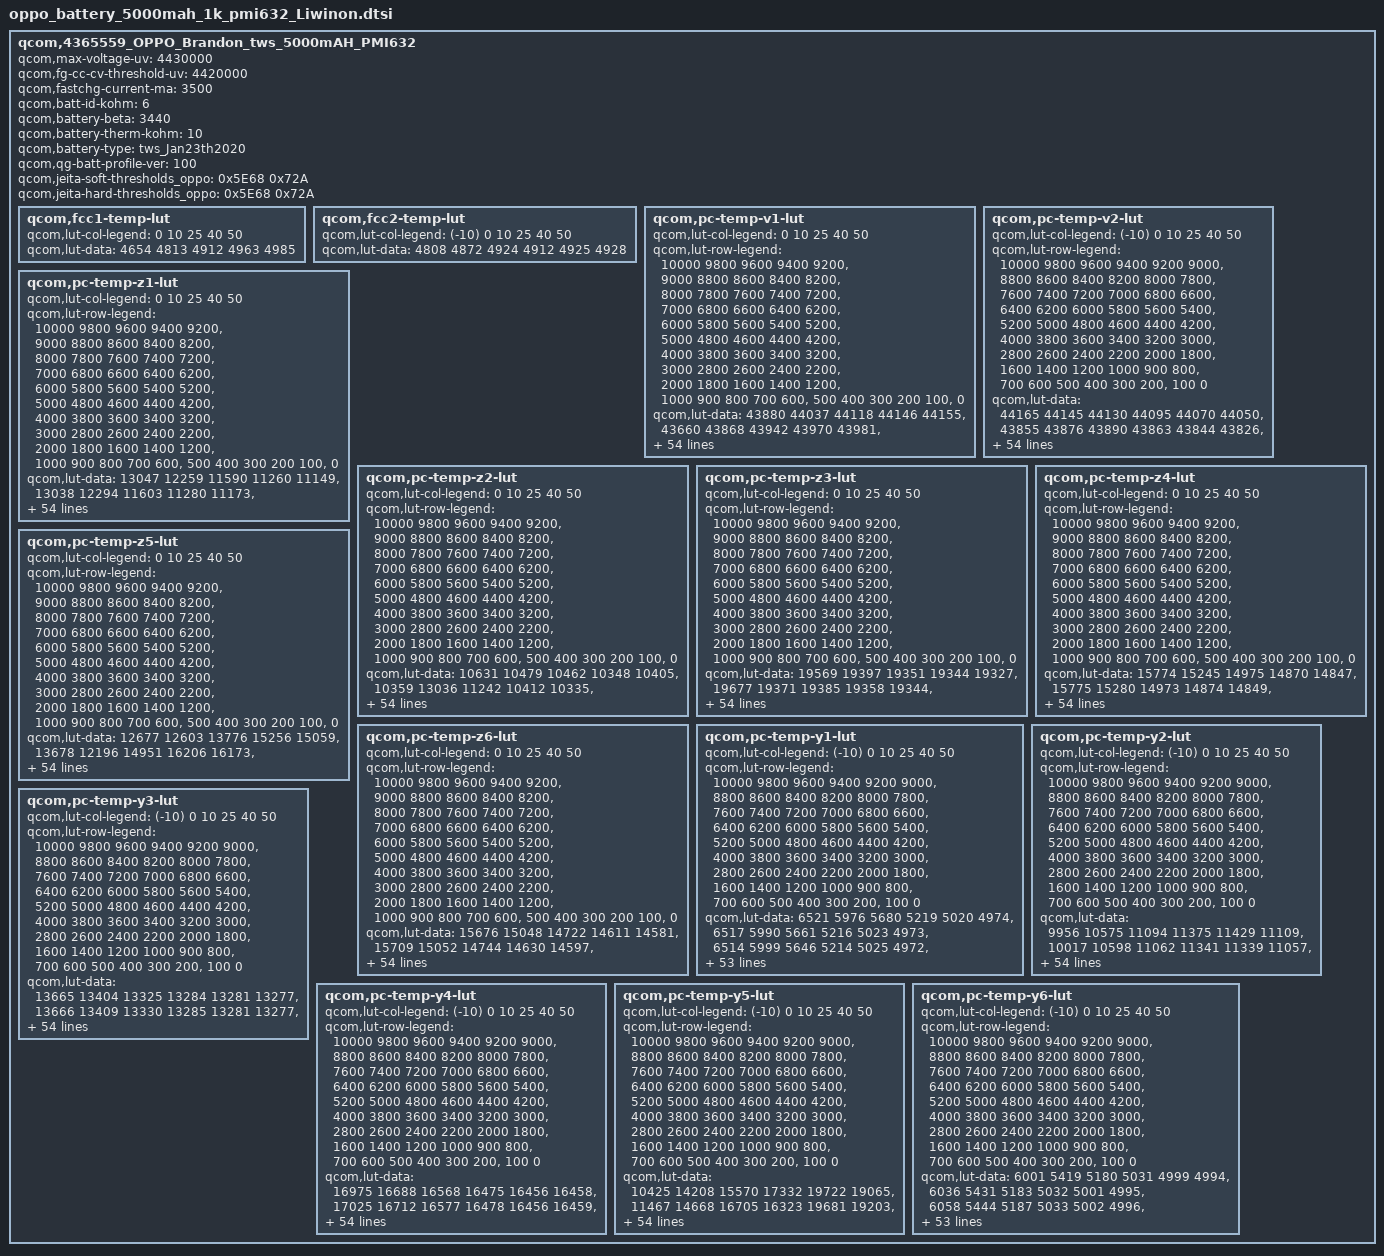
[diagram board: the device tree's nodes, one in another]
qcom,4365559_OPPO_Brandon_tws_5000mAH_PMI632 {
    /* 4365559_OPPO_Brandon_tws_5000mAH_PMI632_averaged_MasterSlave_Jan23th2020 */
    qcom,max-voltage-uv = <4430000>;
    qcom,fg-cc-cv-threshold-uv = <4420000>;
    qcom,fastchg-current-ma = <3500>;
    qcom,batt-id-kohm = <6>;
    qcom,battery-beta = <3440>;
    qcom,battery-therm-kohm = <10>;
    qcom,battery-type = "tws_Jan23th2020";
    qcom,qg-batt-profile-ver = <100>;
    qcom,jeita-soft-thresholds_oppo = <0x5E68 0x72A>;
    qcom,jeita-hard-thresholds_oppo = <0x5E68 0x72A>;

	qcom,fcc1-temp-lut {
		qcom,lut-col-legend = <0 10 25 40 50>;
		qcom,lut-data = <4654 4813 4912 4963 4985>;
	};

	qcom,fcc2-temp-lut {
		qcom,lut-col-legend = <(-10) 0 10 25 40 50>;
		qcom,lut-data = <4808 4872 4924 4912 4925 4928>;
	};

	qcom,pc-temp-v1-lut {
		qcom,lut-col-legend = <0 10 25 40 50>;
		qcom,lut-row-legend = <10000 9800 9600 9400 9200>,
			<9000 8800 8600 8400 8200>,
			<8000 7800 7600 7400 7200>,
			<7000 6800 6600 6400 6200>,
			<6000 5800 5600 5400 5200>,
			<5000 4800 4600 4400 4200>,
			<4000 3800 3600 3400 3200>,
			<3000 2800 2600 2400 2200>,
			<2000 1800 1600 1400 1200>,
			<1000 900 800 700 600>,
			<500 400 300 200 100>,
			<0>;
		qcom,lut-data = <43880 44037 44118 44146 44155>,
			<43660 43868 43942 43970 43981>,
			<43435 43650 43750 43783 43794>,
			<43204 43413 43544 43584 43595>,
			<42971 43181 43326 43372 43383>,
			<42737 42944 43095 43151 43161>,
			<42501 42705 42853 42916 42930>,
			<42265 42464 42611 42675 42691>,
			<42033 42222 42368 42434 42451>,
			<41803 41986 42125 42190 42207>,
			<41578 41754 41888 41950 41966>,
			<41359 41527 41655 41711 41728>,
			<41143 41305 41426 41477 41496>,
			<40934 41088 41197 41251 41267>,
			<40730 40876 40975 41031 41044>,
			<40533 40668 40768 40819 40828>,
			<40340 40469 40571 40614 40621>,
			<40154 40281 40378 40415 40420>,
			<39978 40101 40196 40229 40231>,
			<39814 39922 40009 40050 40053>,
			<39659 39747 39775 39843 39856>,
			<39507 39566 39473 39557 39593>,
			<39361 39351 39218 39281 39323>,
			<39217 39086 39059 39110 39142>,
			<39070 38872 38932 38984 39010>,
			<38923 38745 38819 38869 38890>,
			<38788 38648 38718 38757 38767>,
			<38663 38565 38625 38652 38651>,
			<38553 38493 38535 38552 38546>,
			<38470 38428 38449 38455 38449>,
			<38405 38369 38370 38367 38360>,
			<38351 38315 38297 38286 38279>,
			<38303 38265 38230 38211 38204>,
			<38262 38222 38171 38143 38133>,
			<38225 38181 38120 38079 38066>,
			<38193 38140 38069 38018 37998>,
			<38161 38101 38023 37961 37930>,
			<38118 38053 37972 37903 37858>,
			<38060 37983 37899 37825 37772>,
			<37986 37892 37801 37725 37668>,
			<37891 37790 37695 37615 37555>,
			<37765 37670 37579 37501 37438>,
			<37623 37531 37447 37373 37308>,
			<37466 37365 37284 37213 37150>,
			<37329 37231 37151 37085 37025>,
			<37211 37134 37066 37008 36955>,
			<37176 37105 37041 36980 36928>,
			<37144 37081 37022 36963 36908>,
			<37110 37056 36999 36939 36882>,
			<37068 36999 36937 36865 36797>,
			<36954 36767 36666 36577 36485>,
			<36639 36315 36214 36124 36036>,
			<36132 35730 35626 35544 35453>,
			<35451 34911 34820 34747 34656>,
			<34299 33565 33538 33497 33406>,
			<30000 30000 30000 30000 30000>;
	};

	qcom,pc-temp-v2-lut {
		qcom,lut-col-legend = <(-10) 0 10 25 40 50>;
		qcom,lut-row-legend = <10000 9800 9600 9400 9200 9000>,
			<8800 8600 8400 8200 8000 7800>,
			<7600 7400 7200 7000 6800 6600>,
			<6400 6200 6000 5800 5600 5400>,
			<5200 5000 4800 4600 4400 4200>,
			<4000 3800 3600 3400 3200 3000>,
			<2800 2600 2400 2200 2000 1800>,
			<1600 1400 1200 1000 900 800>,
			<700 600 500 400 300 200>,
			<100 0>;
		qcom,lut-data = <44165 44145 44130 44095 44070 44050>,
			<43855 43876 43890 43863 43844 43826>,
			<43564 43618 43653 43633 43618 43602>,
			<43295 43372 43421 43406 43394 43380>,
			<43051 43143 43195 43183 43173 43161>,
			<42811 42912 42965 42956 42948 42936>,
			<42559 42667 42723 42719 42712 42701>,
			<42302 42416 42475 42477 42470 42460>,
			<42055 42169 42229 42235 42229 42220>,
			<41821 41928 41984 41993 41988 41979>,
			<41590 41692 41744 41754 41749 41742>,
			<41353 41460 41508 41518 41514 41507>,
			<41112 41233 41279 41287 41283 41276>,
			<40869 41011 41059 41062 41059 41052>,
			<40629 40802 40851 40844 40841 40833>,
			<40388 40589 40643 40634 40630 40622>,
			<40140 40350 40423 40432 40428 40420>,
			<39884 40084 40195 40237 40233 40224>,
			<39635 39829 39957 40032 40037 40030>,
			<39401 39596 39696 39809 39839 39838>,
			<39177 39376 39445 39580 39634 39640>,
			<38973 39176 39234 39352 39402 39409>,
			<38788 38992 39049 39120 39146 39152>,
			<38621 38824 38884 38926 38940 38946>,
			<38470 38674 38737 38777 38791 38797>,
			<38329 38536 38604 38650 38666 38671>,
			<38219 38393 38479 38531 38548 38551>,
			<38143 38235 38363 38422 38440 38441>,
			<38081 38101 38258 38322 38342 38341>,
			<38022 38017 38163 38228 38250 38249>,
			<37966 37955 38077 38142 38166 38164>,
			<37910 37904 37992 38064 38090 38087>,
			<37856 37864 37907 37993 38021 38018>,
			<37800 37827 37834 37924 37949 37943>,
			<37743 37782 37783 37856 37866 37851>,
			<37683 37730 37739 37787 37775 37751>,
			<37620 37672 37691 37712 37680 37647>,
			<37553 37613 37642 37628 37577 37536>,
			<37480 37547 37583 37541 37479 37431>,
			<37405 37470 37508 37458 37394 37343>,
			<37325 37379 37415 37373 37313 37260>,
			<37242 37275 37306 37274 37214 37157>,
			<37161 37149 37170 37147 37086 37029>,
			<37081 37016 37021 37021 36966 36911>,
			<37001 36896 36864 36902 36863 36815>,
			<36922 36795 36777 36855 36827 36779>,
			<36877 36755 36744 36837 36814 36766>,
			<36830 36722 36711 36817 36796 36750>,
			<36775 36688 36658 36785 36763 36714>,
			<36711 36633 36556 36691 36647 36574>,
			<36614 36519 36303 36401 36314 36222>,
			<36449 36218 35833 35893 35809 35713>,
			<36165 35636 35160 35242 35156 35050>,
			<35715 34812 34181 34357 34251 34129>,
			<34797 33553 32647 32956 32934 32822>,
			<33915 31826 28647 27850 28081 28044>;
	};

	qcom,pc-temp-z1-lut {
		qcom,lut-col-legend = <0 10 25 40 50>;
		qcom,lut-row-legend = <10000 9800 9600 9400 9200>,
			<9000 8800 8600 8400 8200>,
			<8000 7800 7600 7400 7200>,
			<7000 6800 6600 6400 6200>,
			<6000 5800 5600 5400 5200>,
			<5000 4800 4600 4400 4200>,
			<4000 3800 3600 3400 3200>,
			<3000 2800 2600 2400 2200>,
			<2000 1800 1600 1400 1200>,
			<1000 900 800 700 600>,
			<500 400 300 200 100>,
			<0>;
		qcom,lut-data = <13047 12259 11590 11260 11149>,
			<13038 12294 11603 11280 11173>,
			<13028 12282 11606 11292 11189>,
			<13014 12267 11603 11294 11192>,
			<13000 12254 11599 11295 11193>,
			<12987 12239 11594 11294 11194>,
			<12973 12223 11588 11292 11194>,
			<12960 12205 11581 11289 11194>,
			<12943 12187 11572 11288 11194>,
			<12926 12175 11566 11287 11196>,
			<12917 12165 11564 11286 11196>,
			<12913 12157 11563 11287 11196>,
			<12909 12144 11562 11287 11196>,
			<12897 12129 11561 11288 11196>,
			<12870 12125 11560 11288 11197>,
			<12849 12125 11560 11288 11197>,
			<12840 12125 11561 11288 11198>,
			<12831 12126 11562 11288 11199>,
			<12822 12127 11563 11288 11199>,
			<12810 12128 11565 11289 11199>,
			<12799 12133 11566 11290 11200>,
			<12801 12141 11567 11290 11200>,
			<12817 12147 11568 11290 11200>,
			<12831 12155 11572 11291 11201>,
			<12830 12159 11576 11293 11203>,
			<12823 12159 11580 11295 11206>,
			<12820 12158 11583 11296 11208>,
			<12821 12158 11586 11299 11210>,
			<12825 12167 11589 11301 11212>,
			<12827 12177 11594 11306 11216>,
			<12829 12181 11598 11309 11219>,
			<12831 12185 11603 11311 11221>,
			<12834 12188 11609 11313 11223>,
			<12843 12193 11614 11317 11225>,
			<12853 12199 11619 11321 11229>,
			<12867 12206 11624 11325 11232>,
			<12883 12214 11629 11327 11235>,
			<12891 12222 11633 11330 11237>,
			<12898 12231 11639 11333 11238>,
			<12907 12240 11645 11336 11240>,
			<12918 12251 11652 11339 11241>,
			<12936 12265 11657 11341 11244>,
			<12973 12279 11664 11343 11246>,
			<13018 12291 11671 11346 11247>,
			<12977 12305 11684 11350 11248>,
			<12984 12304 11687 11351 11249>,
			<13003 12303 11688 11350 11248>,
			<12984 12303 11686 11353 11250>,
			<12979 12313 11691 11353 11252>,
			<12994 12319 11700 11358 11254>,
			<12993 12344 11714 11362 11260>,
			<12997 12348 11717 11370 11263>,
			<13046 12371 11735 11378 11273>,
			<13053 12397 11756 11393 11285>,
			<13053 12397 11756 11393 11285>,
			<13053 12397 11756 11393 11285>;
	};

	qcom,pc-temp-z2-lut {
		qcom,lut-col-legend = <0 10 25 40 50>;
		qcom,lut-row-legend = <10000 9800 9600 9400 9200>,
			<9000 8800 8600 8400 8200>,
			<8000 7800 7600 7400 7200>,
			<7000 6800 6600 6400 6200>,
			<6000 5800 5600 5400 5200>,
			<5000 4800 4600 4400 4200>,
			<4000 3800 3600 3400 3200>,
			<3000 2800 2600 2400 2200>,
			<2000 1800 1600 1400 1200>,
			<1000 900 800 700 600>,
			<500 400 300 200 100>,
			<0>;
		qcom,lut-data = <10631 10479 10462 10348 10405>,
			<10359 13036 11242 10412 10335>,
			<10247 11767 11457 10458 10306>,
			<10224 10488 11294 10684 10327>,
			<10213 10345 11094 11169 10419>,
			<10216 10318 10994 11324 10468>,
			<10233 10300 10911 11256 10425>,
			<10245 10282 10807 11138 10369>,
			<10245 10268 10595 10889 10366>,
			<10245 10265 10411 10498 10385>,
			<10245 10265 10536 10364 10396>,
			<10238 10265 10993 10373 10359>,
			<10227 10271 11208 10388 10310>,
			<10222 10286 10907 10532 10302>,
			<10214 10304 10532 10906 10295>,
			<10209 10329 10592 11109 10290>,
			<10210 10360 11035 11154 10288>,
			<10212 10433 11292 11165 10289>,
			<10216 10569 11010 11007 10298>,
			<10230 10633 10605 10553 10319>,
			<10248 10561 10540 10372 10344>,
			<10261 10465 10600 10464 10379>,
			<10270 10458 10641 10556 10414>,
			<10278 10479 10600 10537 10422>,
			<10287 10493 10529 10450 10419>,
			<10296 10491 10515 10410 10420>,
			<10304 10486 10539 10420 10571>,
			<10312 10482 10563 10437 10782>,
			<10318 10477 10573 10464 10788>,
			<10324 10473 10578 10506 10640>,
			<10330 10473 10580 10526 10493>,
			<10336 10474 10591 10511 10361>,
			<10343 10476 10600 10485 10247>,
			<10352 10482 10593 10458 10231>,
			<10361 10491 10580 10422 10244>,
			<10370 10500 10575 10406 10265>,
			<10381 10512 10583 10415 10325>,
			<10394 10526 10597 10435 10406>,
			<10412 10540 10624 10470 10451>,
			<10433 10555 10675 10541 10483>,
			<10452 10566 10708 10594 10502>,
			<10473 10573 10726 10632 10530>,
			<10504 10582 10733 10654 10553>,
			<10568 10601 10720 10662 10508>,
			<10962 10786 10758 10620 10496>,
			<10981 10826 10786 10596 10539>,
			<10954 10865 10750 10571 10489>,
			<10889 10987 10768 10582 10486>,
			<10898 11215 10780 10610 10527>,
			<10908 11261 10831 10671 10615>,
			<10823 11015 10866 10598 10452>,
			<10778 11039 10833 10420 10245>,
			<10526 11011 10787 10339 10156>,
			<10354 10658 10612 10239 10066>,
			<10354 10658 10612 10239 10066>,
			<10354 10658 10612 10239 10066>;
	};

	qcom,pc-temp-z3-lut {
		qcom,lut-col-legend = <0 10 25 40 50>;
		qcom,lut-row-legend = <10000 9800 9600 9400 9200>,
			<9000 8800 8600 8400 8200>,
			<8000 7800 7600 7400 7200>,
			<7000 6800 6600 6400 6200>,
			<6000 5800 5600 5400 5200>,
			<5000 4800 4600 4400 4200>,
			<4000 3800 3600 3400 3200>,
			<3000 2800 2600 2400 2200>,
			<2000 1800 1600 1400 1200>,
			<1000 900 800 700 600>,
			<500 400 300 200 100>,
			<0>;
		qcom,lut-data = <19569 19397 19351 19344 19327>,
			<19677 19371 19385 19358 19344>,
			<19733 19470 19408 19372 19360>,
			<19761 19572 19427 19386 19374>,
			<19775 19588 19444 19403 19388>,
			<19772 19593 19458 19416 19397>,
			<19760 19595 19470 19425 19402>,
			<19750 19595 19474 19431 19404>,
			<19746 19594 19460 19426 19404>,
			<19740 19592 19445 19413 19404>,
			<19736 19579 19451 19405 19403>,
			<19731 19566 19474 19400 19399>,
			<19729 19559 19484 19396 19392>,
			<19730 19552 19460 19396 19387>,
			<19732 19545 19431 19399 19381>,
			<19732 19539 19429 19399 19376>,
			<19731 19534 19440 19394 19372>,
			<19730 19534 19446 19387 19368>,
			<19728 19540 19431 19378 19364>,
			<19723 19543 19410 19365 19360>,
			<19715 19537 19409 19361 19357>,
			<19712 19530 19428 19367 19355>,
			<19710 19534 19440 19374 19353>,
			<19710 19550 19433 19369 19348>,
			<19712 19560 19419 19352 19334>,
			<19718 19558 19409 19343 19326>,
			<19722 19552 19403 19345 19350>,
			<19723 19547 19399 19349 19386>,
			<19722 19541 19401 19357 19396>,
			<19719 19536 19406 19375 19396>,
			<19711 19533 19412 19385 19394>,
			<19703 19530 19419 19386 19387>,
			<19696 19528 19425 19387 19379>,
			<19689 19526 19424 19385 19370>,
			<19682 19525 19422 19378 19359>,
			<19673 19524 19419 19371 19352>,
			<19664 19522 19414 19364 19350>,
			<19656 19520 19410 19358 19347>,
			<19647 19517 19407 19356 19345>,
			<19638 19512 19406 19355 19341>,
			<19629 19507 19404 19355 19339>,
			<19617 19501 19401 19355 19344>,
			<19605 19494 19397 19355 19350>,
			<19585 19485 19394 19356 19352>,
			<19415 19440 19382 19353 19351>,
			<19420 19431 19375 19340 19336>,
			<19340 19419 19370 19338 19329>,
			<19303 19381 19362 19329 19325>,
			<19300 19332 19353 19328 19318>,
			<19296 19336 19345 19322 19316>,
			<19297 19395 19346 19334 19345>,
			<19304 19375 19352 19356 19355>,
			<19317 19340 19355 19352 19356>,
			<19359 19426 19355 19358 19355>,
			<19359 19426 19355 19358 19355>,
			<19359 19426 19355 19358 19355>;
	};

	qcom,pc-temp-z4-lut {
		qcom,lut-col-legend = <0 10 25 40 50>;
		qcom,lut-row-legend = <10000 9800 9600 9400 9200>,
			<9000 8800 8600 8400 8200>,
			<8000 7800 7600 7400 7200>,
			<7000 6800 6600 6400 6200>,
			<6000 5800 5600 5400 5200>,
			<5000 4800 4600 4400 4200>,
			<4000 3800 3600 3400 3200>,
			<3000 2800 2600 2400 2200>,
			<2000 1800 1600 1400 1200>,
			<1000 900 800 700 600>,
			<500 400 300 200 100>,
			<0>;
		qcom,lut-data = <15774 15245 14975 14870 14847>,
			<15775 15280 14973 14874 14849>,
			<15754 15225 14958 14875 14848>,
			<15642 15148 14919 14859 14841>,
			<15496 15082 14872 14817 14815>,
			<15397 15016 14832 14782 14790>,
			<15319 14960 14793 14754 14772>,
			<15249 14913 14774 14734 14756>,
			<15187 14875 14769 14726 14737>,
			<15131 14849 14765 14724 14716>,
			<15083 14830 14739 14720 14705>,
			<15039 14812 14680 14713 14701>,
			<14999 14793 14653 14704 14699>,
			<14961 14775 14674 14692 14697>,
			<14925 14761 14700 14674 14693>,
			<14894 14753 14696 14665 14689>,
			<14869 14744 14663 14661 14684>,
			<14846 14729 14644 14659 14680>,
			<14826 14707 14654 14661 14678>,
			<14806 14696 14676 14669 14676>,
			<14790 14701 14706 14683 14676>,
			<14781 14713 14760 14739 14724>,
			<14774 14735 14799 14799 14793>,
			<14771 14785 14811 14813 14811>,
			<14772 14817 14818 14820 14816>,
			<14776 14816 14818 14822 14818>,
			<14781 14812 14809 14811 14784>,
			<14790 14807 14795 14791 14731>,
			<14800 14797 14780 14767 14708>,
			<14801 14785 14761 14736 14695>,
			<14798 14774 14743 14712 14687>,
			<14793 14764 14725 14696 14683>,
			<14787 14754 14711 14685 14680>,
			<14779 14743 14702 14683 14679>,
			<14770 14733 14696 14682 14679>,
			<14762 14726 14694 14682 14678>,
			<14753 14719 14693 14682 14678>,
			<14744 14715 14693 14684 14678>,
			<14736 14715 14695 14688 14682>,
			<14729 14715 14701 14699 14698>,
			<14725 14715 14704 14705 14708>,
			<14722 14708 14699 14699 14699>,
			<14714 14702 14693 14694 14690>,
			<14704 14697 14691 14693 14691>,
			<14791 14684 14676 14680 14678>,
			<14775 14672 14660 14671 14666>,
			<14861 14677 14655 14664 14665>,
			<14900 14710 14651 14655 14651>,
			<14899 14760 14649 14638 14635>,
			<14897 14753 14654 14639 14631>,
			<14893 14690 14675 14663 14650>,
			<14893 14728 14679 14654 14653>,
			<14897 14775 14680 14662 14659>,
			<14884 14704 14688 14661 14663>,
			<14884 14704 14688 14661 14663>,
			<14884 14704 14688 14661 14663>;
	};

	qcom,pc-temp-z5-lut {
		qcom,lut-col-legend = <0 10 25 40 50>;
		qcom,lut-row-legend = <10000 9800 9600 9400 9200>,
			<9000 8800 8600 8400 8200>,
			<8000 7800 7600 7400 7200>,
			<7000 6800 6600 6400 6200>,
			<6000 5800 5600 5400 5200>,
			<5000 4800 4600 4400 4200>,
			<4000 3800 3600 3400 3200>,
			<3000 2800 2600 2400 2200>,
			<2000 1800 1600 1400 1200>,
			<1000 900 800 700 600>,
			<500 400 300 200 100>,
			<0>;
		qcom,lut-data = <12677 12603 13776 15256 15059>,
			<13678 12196 14951 16206 16173>,
			<14275 14059 15673 17120 17364>,
			<14609 16142 16349 18000 18661>,
			<14799 16779 17191 19142 20159>,
			<14880 17092 18460 20514 21411>,
			<14978 17468 20127 22630 22212>,
			<15099 18190 20699 24148 22970>,
			<15335 18886 20036 23758 24326>,
			<15653 19067 19302 22617 26506>,
			<15942 19082 22307 22221 27839>,
			<16310 19121 32123 22738 27734>,
			<16756 19493 36778 23693 27270>,
			<17275 20264 31354 25826 27236>,
			<18013 21060 24586 29667 27440>,
			<18806 21865 25303 31795 27810>,
			<19710 22894 31941 32463 28446>,
			<20931 25101 35773 32724 29205>,
			<22254 28889 32153 31246 29880>,
			<23605 31005 26906 27008 30606>,
			<25067 31449 28664 25529 30925>,
			<26704 32385 42905 28413 29714>,
			<28625 36798 52612 31425 27220>,
			<31043 48786 45458 29377 23936>,
			<34917 56514 32153 21932 18798>,
			<40221 52576 25810 17970 16192>,
			<43611 44394 22651 17339 19175>,
			<45343 39017 21176 17011 23709>,
			<46386 35357 21315 17556 25495>,
			<45812 33095 21833 19922 27375>,
			<43509 32580 22820 22603 28567>,
			<41139 32302 26226 25760 28905>,
			<39837 32245 29979 28638 29097>,
			<38841 33128 32536 29890 28879>,
			<37837 34655 35033 30800 27751>,
			<36484 36262 35807 31139 27064>,
			<35289 38410 35703 30293 27869>,
			<34982 39662 35504 28986 29052>,
			<35141 39793 35165 28284 28662>,
			<35264 39852 34499 27659 25764>,
			<34865 39503 33603 26906 23940>,
			<33961 36792 31426 25560 24420>,
			<33921 34818 29798 24727 25167>,
			<34425 33837 29340 25416 26572>,
			<19999 28297 29599 25963 27472>,
			<18708 27431 28812 22020 21965>,
			<14270 23600 26731 21948 19854>,
			<12191 17022 24403 20395 20346>,
			<12112 13548 21747 23476 22429>,
			<12078 14143 19694 21508 22792>,
			<12123 19215 18427 19566 25921>,
			<12262 15901 17812 22615 24239>,
			<12341 13661 18068 19413 21262>,
			<13830 20407 17059 19272 18677>,
			<13830 20407 17059 19272 18677>,
			<13830 20407 17059 19272 18677>;
	};

	qcom,pc-temp-z6-lut {
		qcom,lut-col-legend = <0 10 25 40 50>;
		qcom,lut-row-legend = <10000 9800 9600 9400 9200>,
			<9000 8800 8600 8400 8200>,
			<8000 7800 7600 7400 7200>,
			<7000 6800 6600 6400 6200>,
			<6000 5800 5600 5400 5200>,
			<5000 4800 4600 4400 4200>,
			<4000 3800 3600 3400 3200>,
			<3000 2800 2600 2400 2200>,
			<2000 1800 1600 1400 1200>,
			<1000 900 800 700 600>,
			<500 400 300 200 100>,
			<0>;
		qcom,lut-data = <15676 15048 14722 14611 14581>,
			<15709 15052 14744 14630 14597>,
			<15709 15061 14750 14640 14606>,
			<15659 15068 14742 14638 14607>,
			<15587 15057 14731 14632 14605>,
			<15531 15020 14721 14626 14603>,
			<15480 14985 14710 14620 14598>,
			<15435 14961 14700 14614 14592>,
			<15396 14939 14690 14607 14586>,
			<15361 14920 14680 14599 14578>,
			<15330 14901 14669 14592 14571>,
			<15301 14885 14659 14585 14566>,
			<15276 14870 14651 14580 14562>,
			<15253 14856 14646 14574 14557>,
			<15233 14845 14642 14569 14553>,
			<15215 14837 14637 14564 14548>,
			<15198 14831 14630 14559 14544>,
			<15183 14825 14626 14555 14540>,
			<15170 14819 14624 14552 14536>,
			<15155 14817 14622 14549 14532>,
			<15143 14817 14629 14549 14531>,
			<15140 14819 14664 14577 14552>,
			<15139 14827 14688 14607 14580>,
			<15139 14859 14687 14609 14584>,
			<15141 14879 14685 14605 14581>,
			<15147 14878 14683 14601 14577>,
			<15152 14876 14676 14597 14575>,
			<15159 14872 14669 14592 14572>,
			<15164 14866 14664 14587 14569>,
			<15164 14859 14659 14583 14564>,
			<15161 14854 14655 14579 14560>,
			<15156 14850 14652 14574 14554>,
			<15151 14846 14649 14570 14549>,
			<15146 14841 14646 14566 14544>,
			<15141 14838 14643 14563 14539>,
			<15135 14836 14641 14560 14535>,
			<15130 14834 14638 14556 14533>,
			<15127 14834 14636 14554 14531>,
			<15125 14834 14637 14554 14532>,
			<15124 14835 14640 14559 14536>,
			<15124 14835 14642 14561 14539>,
			<15124 14832 14639 14559 14538>,
			<15122 14829 14636 14557 14537>,
			<15117 14827 14634 14558 14539>,
			<15081 14805 14624 14551 14534>,
			<15081 14797 14614 14540 14521>,
			<15076 14792 14609 14536 14516>,
			<15074 14789 14603 14528 14508>,
			<15074 14788 14599 14520 14497>,
			<15075 14791 14598 14518 14495>,
			<15082 14800 14610 14535 14519>,
			<15095 14811 14618 14546 14529>,
			<15115 14823 14624 14549 14534>,
			<15145 14849 14634 14555 14539>,
			<15145 14849 14634 14555 14539>,
			<15145 14849 14634 14555 14539>;
	};

	qcom,pc-temp-y1-lut {
		qcom,lut-col-legend = <(-10) 0 10 25 40 50>;
		qcom,lut-row-legend = <10000 9800 9600 9400 9200 9000>,
			<8800 8600 8400 8200 8000 7800>,
			<7600 7400 7200 7000 6800 6600>,
			<6400 6200 6000 5800 5600 5400>,
			<5200 5000 4800 4600 4400 4200>,
			<4000 3800 3600 3400 3200 3000>,
			<2800 2600 2400 2200 2000 1800>,
			<1600 1400 1200 1000 900 800>,
			<700 600 500 400 300 200>,
			<100 0>;
		qcom,lut-data = <6521 5976 5680 5219 5020 4974>,
			<6517 5990 5661 5216 5023 4973>,
			<6514 5999 5646 5214 5025 4972>,
			<6512 6004 5634 5212 5027 4970>,
			<6510 6007 5626 5210 5028 4969>,
			<6509 6008 5622 5208 5029 4969>,
			<6515 6007 5626 5207 5028 4969>,
			<6531 6005 5633 5205 5027 4969>,
			<6536 6003 5634 5204 5026 4969>,
			<6520 5996 5625 5203 5025 4970>,
			<6502 5990 5617 5202 5024 4970>,
			<6504 5991 5617 5201 5025 4970>,
			<6519 5991 5618 5200 5026 4969>,
			<6527 5993 5617 5200 5027 4969>,
			<6520 6009 5610 5200 5024 4971>,
			<6510 6027 5603 5199 5023 4973>,
			<6510 6026 5603 5200 5023 4973>,
			<6520 6015 5606 5202 5026 4973>,
			<6531 6007 5608 5203 5027 4972>,
			<6537 6011 5609 5203 5026 4971>,
			<6541 6021 5611 5204 5026 4969>,
			<6542 6022 5615 5206 5026 4969>,
			<6525 6011 5622 5209 5028 4970>,
			<6503 6002 5624 5212 5029 4971>,
			<6500 6011 5620 5214 5030 4971>,
			<6503 6025 5615 5215 5030 4973>,
			<6507 6028 5614 5217 5031 4974>,
			<6510 6021 5612 5220 5033 4975>,
			<6512 6015 5612 5222 5035 4977>,
			<6515 6019 5613 5225 5037 4979>,
			<6520 6027 5615 5227 5038 4981>,
			<6519 6029 5621 5231 5040 4982>,
			<6508 6021 5637 5236 5043 4984>,
			<6490 6013 5649 5240 5045 4985>,
			<6485 6012 5652 5242 5044 4987>,
			<6504 6011 5653 5244 5043 4988>,
			<6527 6010 5654 5246 5044 4989>,
			<6522 6006 5653 5250 5047 4989>,
			<6485 6001 5653 5253 5049 4989>,
			<6460 5999 5657 5254 5050 4989>,
			<6468 6009 5664 5254 5050 4989>,
			<6486 6019 5671 5256 5050 4990>,
			<6489 6016 5678 5260 5049 4992>,
			<6470 6008 5680 5266 5050 4993>,
			<6452 5997 5675 5275 5056 4994>,
			<6442 5996 5673 5286 5058 4996>,
			<6441 6006 5686 5288 5058 4995>,
			<6441 6037 5696 5288 5058 4997>,
			<6454 6022 5689 5287 5059 4996>,
			<6505 6015 5690 5288 5058 4997>,
			<6595 6030 5690 5292 5062 5003>,
			<6667 6055 5698 5307 5069 5005>,
			<6727 6151 5743 5338 5075 5011>,
			<6882 6363 5846 5379 5085 5021>,
			<6882 6363 5846 5379 5085 5021>,
			<6882 6363 5846 5379 5085 5021>;
	};

	qcom,pc-temp-y2-lut {
		qcom,lut-col-legend = <(-10) 0 10 25 40 50>;
		qcom,lut-row-legend = <10000 9800 9600 9400 9200 9000>,
			<8800 8600 8400 8200 8000 7800>,
			<7600 7400 7200 7000 6800 6600>,
			<6400 6200 6000 5800 5600 5400>,
			<5200 5000 4800 4600 4400 4200>,
			<4000 3800 3600 3400 3200 3000>,
			<2800 2600 2400 2200 2000 1800>,
			<1600 1400 1200 1000 900 800>,
			<700 600 500 400 300 200>,
			<100 0>;
		qcom,lut-data = <9956 10575 11094 11375 11429 11109>,
			<10017 10598 11062 11341 11339 11057>,
			<10075 10627 11031 11280 11216 11005>,
			<10129 10656 11003 11211 11088 10958>,
			<10178 10680 10976 11153 10985 10923>,
			<10219 10694 10953 11123 10937 10904>,
			<10249 10695 10930 11118 10942 10894>,
			<10273 10694 10911 11116 10957 10881>,
			<10308 10697 10906 11113 10960 10876>,
			<10385 10711 10907 11100 10946 10873>,
			<10471 10732 10910 11088 10933 10868>,
			<10525 10756 10926 11083 10937 10849>,
			<10563 10790 10960 11075 10948 10818>,
			<10604 10830 10993 11077 10951 10813>,
			<10656 10897 11025 11133 10937 10862>,
			<10714 10955 11060 11198 10932 10912>,
			<10780 10965 11115 11221 10972 10918>,
			<10867 10967 11183 11235 11060 10919>,
			<10924 10969 11204 11246 11163 10943>,
			<10655 10988 11185 11296 11322 11123>,
			<10004 11020 11165 11351 11447 11300>,
			<9719 11055 11171 11359 11405 11275>,
			<9700 11098 11200 11353 11251 11162>,
			<9690 11127 11227 11350 11182 11112>,
			<9685 11131 11247 11348 11202 11128>,
			<9681 11131 11264 11348 11236 11153>,
			<9679 11124 11284 11361 11264 11173>,
			<9677 11102 11305 11391 11297 11194>,
			<9674 11070 11316 11416 11317 11224>,
			<9672 11032 11319 11432 11324 11307>,
			<9670 10984 11319 11447 11338 11404>,
			<9668 10932 11314 11457 11388 11455>,
			<9667 10875 11300 11476 11516 11506>,
			<9666 10790 11280 11487 11589 11532>,
			<9665 10560 11251 11480 11516 11501>,
			<9664 10084 11211 11464 11395 11447>,
			<9663 9798 11161 11455 11344 11413>,
			<9663 9733 11095 11451 11316 11393>,
			<9663 9695 11022 11446 11302 11370>,
			<9663 9680 10950 11430 11298 11299>,
			<9662 9671 10872 11402 11288 11205>,
			<9662 9666 10779 11372 11272 11169>,
			<9661 9663 10668 11338 11238 11160>,
			<9661 9661 10458 11295 11182 11122>,
			<9660 9660 10039 11235 11093 10979>,
			<9658 9658 9821 11161 11038 10849>,
			<9657 9658 9807 11158 11058 10922>,
			<9656 9657 9753 11159 11078 10906>,
			<9654 9656 9691 11164 11072 10934>,
			<9652 9655 9668 11167 11057 10899>,
			<9650 9653 9658 11106 10977 10818>,
			<9649 9649 9654 10978 10937 10714>,
			<9648 9648 9651 10847 10847 10636>,
			<9648 9648 9650 10659 10708 10502>,
			<9648 9648 9650 10659 10708 10502>,
			<9648 9648 9650 10659 10708 10502>;
	};

	qcom,pc-temp-y3-lut {
		qcom,lut-col-legend = <(-10) 0 10 25 40 50>;
		qcom,lut-row-legend = <10000 9800 9600 9400 9200 9000>,
			<8800 8600 8400 8200 8000 7800>,
			<7600 7400 7200 7000 6800 6600>,
			<6400 6200 6000 5800 5600 5400>,
			<5200 5000 4800 4600 4400 4200>,
			<4000 3800 3600 3400 3200 3000>,
			<2800 2600 2400 2200 2000 1800>,
			<1600 1400 1200 1000 900 800>,
			<700 600 500 400 300 200>,
			<100 0>;
		qcom,lut-data = <13665 13404 13325 13284 13281 13277>,
			<13666 13409 13330 13285 13281 13277>,
			<13667 13416 13334 13286 13281 13278>,
			<13667 13423 13339 13288 13282 13280>,
			<13668 13430 13343 13290 13283 13281>,
			<13667 13433 13345 13291 13284 13281>,
			<13662 13433 13347 13294 13285 13282>,
			<13647 13433 13348 13297 13286 13283>,
			<13634 13432 13349 13298 13286 13283>,
			<13626 13430 13349 13299 13286 13284>,
			<13618 13427 13349 13299 13287 13285>,
			<13601 13425 13349 13299 13287 13285>,
			<13569 13425 13347 13299 13287 13285>,
			<13544 13423 13347 13299 13288 13286>,
			<13533 13421 13348 13300 13290 13287>,
			<13524 13417 13349 13302 13293 13288>,
			<13510 13412 13348 13302 13294 13289>,
			<13485 13405 13347 13301 13294 13289>,
			<13463 13397 13345 13300 13294 13290>,
			<13452 13390 13339 13301 13294 13290>,
			<13444 13384 13332 13301 13293 13290>,
			<13440 13378 13328 13300 13290 13288>,
			<13437 13373 13326 13295 13283 13281>,
			<13434 13368 13324 13291 13279 13278>,
			<13433 13362 13323 13291 13279 13278>,
			<13432 13356 13322 13290 13279 13279>,
			<13431 13349 13320 13290 13279 13278>,
			<13441 13341 13319 13290 13279 13278>,
			<13463 13334 13318 13290 13279 13277>,
			<13487 13330 13317 13290 13279 13277>,
			<13517 13327 13317 13291 13279 13277>,
			<13549 13326 13317 13291 13279 13278>,
			<13583 13336 13315 13291 13281 13278>,
			<13621 13349 13314 13291 13282 13279>,
			<13661 13358 13315 13291 13281 13279>,
			<13705 13366 13317 13291 13280 13279>,
			<13750 13376 13319 13291 13280 13279>,
			<13791 13399 13322 13290 13279 13279>,
			<13830 13434 13325 13289 13279 13278>,
			<13869 13472 13329 13289 13280 13279>,
			<13908 13519 13334 13289 13281 13280>,
			<13950 13576 13338 13289 13281 13280>,
			<13995 13657 13343 13290 13280 13279>,
			<14042 13755 13347 13290 13280 13279>,
			<14114 13852 13351 13292 13281 13280>,
			<14253 13958 13379 13298 13288 13286>,
			<14365 14015 13382 13299 13290 13288>,
			<14543 14062 13407 13300 13292 13290>,
			<14797 14169 13467 13305 13294 13291>,
			<15519 14393 13595 13307 13293 13287>,
			<17538 15031 13871 13304 13287 13284>,
			<22373 17744 14516 13305 13289 13285>,
			<34778 26935 16867 13314 13295 13289>,
			<65535 65535 28266 13334 13300 13297>,
			<65535 65535 28266 13334 13300 13297>,
			<65535 65535 28266 13334 13300 13297>;
	};

	qcom,pc-temp-y4-lut {
		qcom,lut-col-legend = <(-10) 0 10 25 40 50>;
		qcom,lut-row-legend = <10000 9800 9600 9400 9200 9000>,
			<8800 8600 8400 8200 8000 7800>,
			<7600 7400 7200 7000 6800 6600>,
			<6400 6200 6000 5800 5600 5400>,
			<5200 5000 4800 4600 4400 4200>,
			<4000 3800 3600 3400 3200 3000>,
			<2800 2600 2400 2200 2000 1800>,
			<1600 1400 1200 1000 900 800>,
			<700 600 500 400 300 200>,
			<100 0>;
		qcom,lut-data = <16975 16688 16568 16475 16456 16458>,
			<17025 16712 16577 16478 16456 16459>,
			<17092 16753 16590 16481 16457 16459>,
			<17161 16801 16603 16484 16458 16460>,
			<17216 16841 16615 16485 16460 16461>,
			<17244 16863 16621 16486 16461 16461>,
			<17242 16866 16623 16486 16463 16462>,
			<17231 16867 16624 16485 16464 16462>,
			<17219 16870 16626 16486 16465 16463>,
			<17200 16882 16632 16491 16469 16464>,
			<17184 16896 16640 16497 16473 16467>,
			<17184 16905 16652 16505 16477 16470>,
			<17193 16912 16670 16514 16483 16474>,
			<17199 16919 16690 16524 16488 16479>,
			<17168 16931 16719 16532 16492 16482>,
			<17104 16940 16739 16543 16497 16486>,
			<17046 16927 16737 16564 16506 16493>,
			<16986 16869 16726 16595 16521 16504>,
			<16943 16813 16708 16607 16535 16516>,
			<16929 16777 16659 16595 16552 16535>,
			<16921 16747 16606 16575 16565 16549>,
			<16908 16722 16580 16546 16548 16535>,
			<16864 16701 16562 16500 16494 16489>,
			<16814 16683 16552 16477 16468 16466>,
			<16784 16669 16548 16477 16466 16464>,
			<16759 16657 16545 16477 16466 16462>,
			<16747 16637 16544 16478 16467 16464>,
			<16747 16594 16543 16482 16473 16469>,
			<16749 16561 16542 16487 16480 16475>,
			<16751 16567 16541 16493 16488 16483>,
			<16757 16585 16540 16499 16498 16491>,
			<16763 16597 16535 16506 16507 16500>,
			<16767 16601 16521 16515 16516 16512>,
			<16772 16606 16513 16519 16520 16517>,
			<16776 16622 16519 16518 16516 16513>,
			<16779 16660 16531 16515 16508 16504>,
			<16781 16689 16545 16509 16498 16494>,
			<16781 16703 16563 16493 16481 16480>,
			<16779 16713 16579 16482 16470 16472>,
			<16778 16717 16592 16484 16474 16476>,
			<16777 16720 16603 16490 16480 16482>,
			<16776 16721 16609 16492 16481 16483>,
			<16778 16710 16612 16492 16476 16475>,
			<16795 16695 16617 16491 16468 16465>,
			<16816 16694 16624 16486 16459 16454>,
			<16839 16703 16647 16503 16478 16484>,
			<16850 16714 16647 16510 16495 16508>,
			<16858 16710 16661 16518 16522 16539>,
			<16846 16720 16699 16549 16554 16566>,
			<16904 16747 16746 16560 16543 16542>,
			<17228 16785 16750 16531 16489 16484>,
			<18043 17099 16769 16511 16472 16476>,
			<20578 19146 17227 16535 16476 16476>,
			<32992 26387 23162 16586 16495 16488>,
			<32992 26387 23162 16586 16495 16488>,
			<32992 26387 23162 16586 16495 16488>;
	};

	qcom,pc-temp-y5-lut {
		qcom,lut-col-legend = <(-10) 0 10 25 40 50>;
		qcom,lut-row-legend = <10000 9800 9600 9400 9200 9000>,
			<8800 8600 8400 8200 8000 7800>,
			<7600 7400 7200 7000 6800 6600>,
			<6400 6200 6000 5800 5600 5400>,
			<5200 5000 4800 4600 4400 4200>,
			<4000 3800 3600 3400 3200 3000>,
			<2800 2600 2400 2200 2000 1800>,
			<1600 1400 1200 1000 900 800>,
			<700 600 500 400 300 200>,
			<100 0>;
		qcom,lut-data = <10425 14208 15570 17332 19722 19065>,
			<11467 14668 16705 16323 19681 19203>,
			<12543 15291 17500 15857 19439 19267>,
			<13570 15936 18008 15753 19084 19270>,
			<14465 16463 18280 15831 18709 19221>,
			<15145 16731 18365 15908 18405 19133>,
			<15559 16729 18195 16211 18064 18710>,
			<15857 16666 17786 16762 17661 18017>,
			<16286 16636 17363 16838 17422 17701>,
			<17240 16574 16852 16400 16869 17478>,
			<18103 16525 16420 15830 16263 17226>,
			<18146 16616 16163 15252 15753 16769>,
			<17914 16912 15971 14655 15219 16094>,
			<17781 17341 15971 14478 15098 15719>,
			<18787 18319 16649 14496 15431 15711>,
			<20397 19460 17760 14523 15742 15799>,
			<20749 20144 19512 14553 15607 15595>,
			<20296 20662 21949 14634 15226 15081>,
			<19571 20918 22787 14904 15188 15013>,
			<18296 20956 22348 18143 17189 16448>,
			<16458 20965 21846 21736 19302 17959>,
			<15583 21060 21721 21929 19248 18155>,
			<15385 21302 21659 21216 18529 18141>,
			<15225 21604 21655 20610 18067 18158>,
			<14681 22052 21820 20202 17971 18408>,
			<13386 22547 22008 19882 17924 18605>,
			<12619 22380 21926 19796 17672 18114>,
			<12626 19627 21550 19889 17090 16793>,
			<12721 16601 21363 19960 16754 16100>,
			<12808 15176 22696 20082 16668 16045>,
			<12897 14125 24491 20345 16650 16018>,
			<12998 13865 24521 20655 17005 16120>,
			<13136 15124 23314 21239 18323 16677>,
			<13326 16546 22286 21962 19469 17411>,
			<13487 16370 21722 22995 20049 18456>,
			<13612 15117 21185 24110 20462 19682>,
			<13721 14390 20799 24246 20554 20582>,
			<13802 14444 20440 22991 20319 21388>,
			<13823 14544 20104 21486 20141 21772>,
			<13794 14554 19789 20378 20153 21492>,
			<13678 14510 19455 19355 20158 20979>,
			<13503 14459 19101 18966 20183 20835>,
			<13370 14340 18671 19118 20247 21254>,
			<13039 14259 17632 19172 19756 20931>,
			<12923 14042 15178 19120 18106 19151>,
			<13154 13634 14435 18440 18039 17244>,
			<13259 13477 14223 18304 17897 16528>,
			<13430 13624 14168 18310 17392 16322>,
			<13532 13881 13972 18563 17249 16059>,
			<12996 13885 14011 18580 16737 15290>,
			<11596 13820 14109 18207 16445 15723>,
			<10227 11500 13637 19208 18019 15976>,
			<9407 9608 11781 19395 19808 16402>,
			<9073 10361 9598 20287 23685 22509>,
			<9073 10361 9598 20287 23685 22509>,
			<9073 10361 9598 20287 23685 22509>;
	};

	qcom,pc-temp-y6-lut {
		qcom,lut-col-legend = <(-10) 0 10 25 40 50>;
		qcom,lut-row-legend = <10000 9800 9600 9400 9200 9000>,
			<8800 8600 8400 8200 8000 7800>,
			<7600 7400 7200 7000 6800 6600>,
			<6400 6200 6000 5800 5600 5400>,
			<5200 5000 4800 4600 4400 4200>,
			<4000 3800 3600 3400 3200 3000>,
			<2800 2600 2400 2200 2000 1800>,
			<1600 1400 1200 1000 900 800>,
			<700 600 500 400 300 200>,
			<100 0>;
		qcom,lut-data = <6001 5419 5180 5031 4999 4994>,
			<6036 5431 5183 5032 5001 4995>,
			<6058 5444 5187 5033 5002 4996>,
			<6069 5457 5191 5035 5003 4997>,
			<6074 5466 5194 5036 5004 4998>,
			<6075 5470 5196 5037 5005 4998>,
			<6068 5469 5195 5039 5007 4999>,
			<6050 5465 5195 5040 5008 5000>,
			<6035 5463 5194 5042 5009 5001>,
			<6025 5462 5195 5044 5010 5002>,
			<6014 5461 5195 5046 5011 5003>,
			<6002 5461 5196 5048 5013 5004>,
			<5988 5461 5199 5050 5014 5005>,
			<5973 5461 5203 5053 5016 5007>,
			<5958 5461 5211 5056 5019 5009>,
			<5942 5461 5217 5061 5022 5011>,
			<5924 5456 5216 5067 5026 5014>,
			<5902 5435 5211 5075 5031 5017>,
			<5882 5415 5204 5077 5034 5021>,
			<5865 5402 5186 5074 5038 5026>,
			<5849 5391 5166 5068 5041 5030>,
			<5838 5383 5156 5059 5034 5024>,
			<5830 5377 5149 5042 5013 5005>,
			<5824 5372 5146 5034 5003 4996>,
			<5824 5369 5144 5033 5003 4996>,
			<5826 5367 5144 5033 5003 4996>,
			<5828 5364 5143 5034 5003 4996>,
			<5844 5355 5143 5035 5005 4997>,
			<5873 5349 5143 5037 5007 4999>,
			<5901 5354 5145 5039 5009 5001>,
			<5932 5370 5146 5041 5012 5003>,
			<5964 5389 5146 5044 5015 5007>,
			<5999 5414 5144 5047 5019 5010>,
			<6036 5445 5143 5049 5021 5012>,
			<6072 5478 5147 5049 5019 5011>,
			<6109 5514 5156 5048 5016 5009>,
			<6146 5555 5166 5047 5013 5006>,
			<6180 5602 5179 5042 5008 5002>,
			<6213 5655 5194 5038 5005 4999>,
			<6245 5715 5212 5039 5007 5001>,
			<6276 5782 5232 5041 5010 5004>,
			<6309 5857 5256 5043 5010 5004>,
			<6348 5942 5285 5044 5008 5001>,
			<6394 6033 5322 5046 5006 4999>,
			<6464 6120 5372 5048 5005 4997>,
			<6591 6216 5457 5059 5015 5010>,
			<6697 6269 5471 5062 5022 5018>,
			<6865 6315 5519 5064 5031 5029>,
			<7092 6412 5632 5077 5042 5037>,
			<7721 6607 5817 5082 5037 5028>,
			<9412 7138 6105 5072 5018 5009>,
			<13180 9311 6651 5071 5016 5009>,
			<22526 16340 8567 5093 5022 5012>,
			<51137 45423 18090 5140 5033 5023>,
			<51137 45423 18090 5140 5033 5023>,
			<51137 45423 18090 5140 5033 5023>;
	};

};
